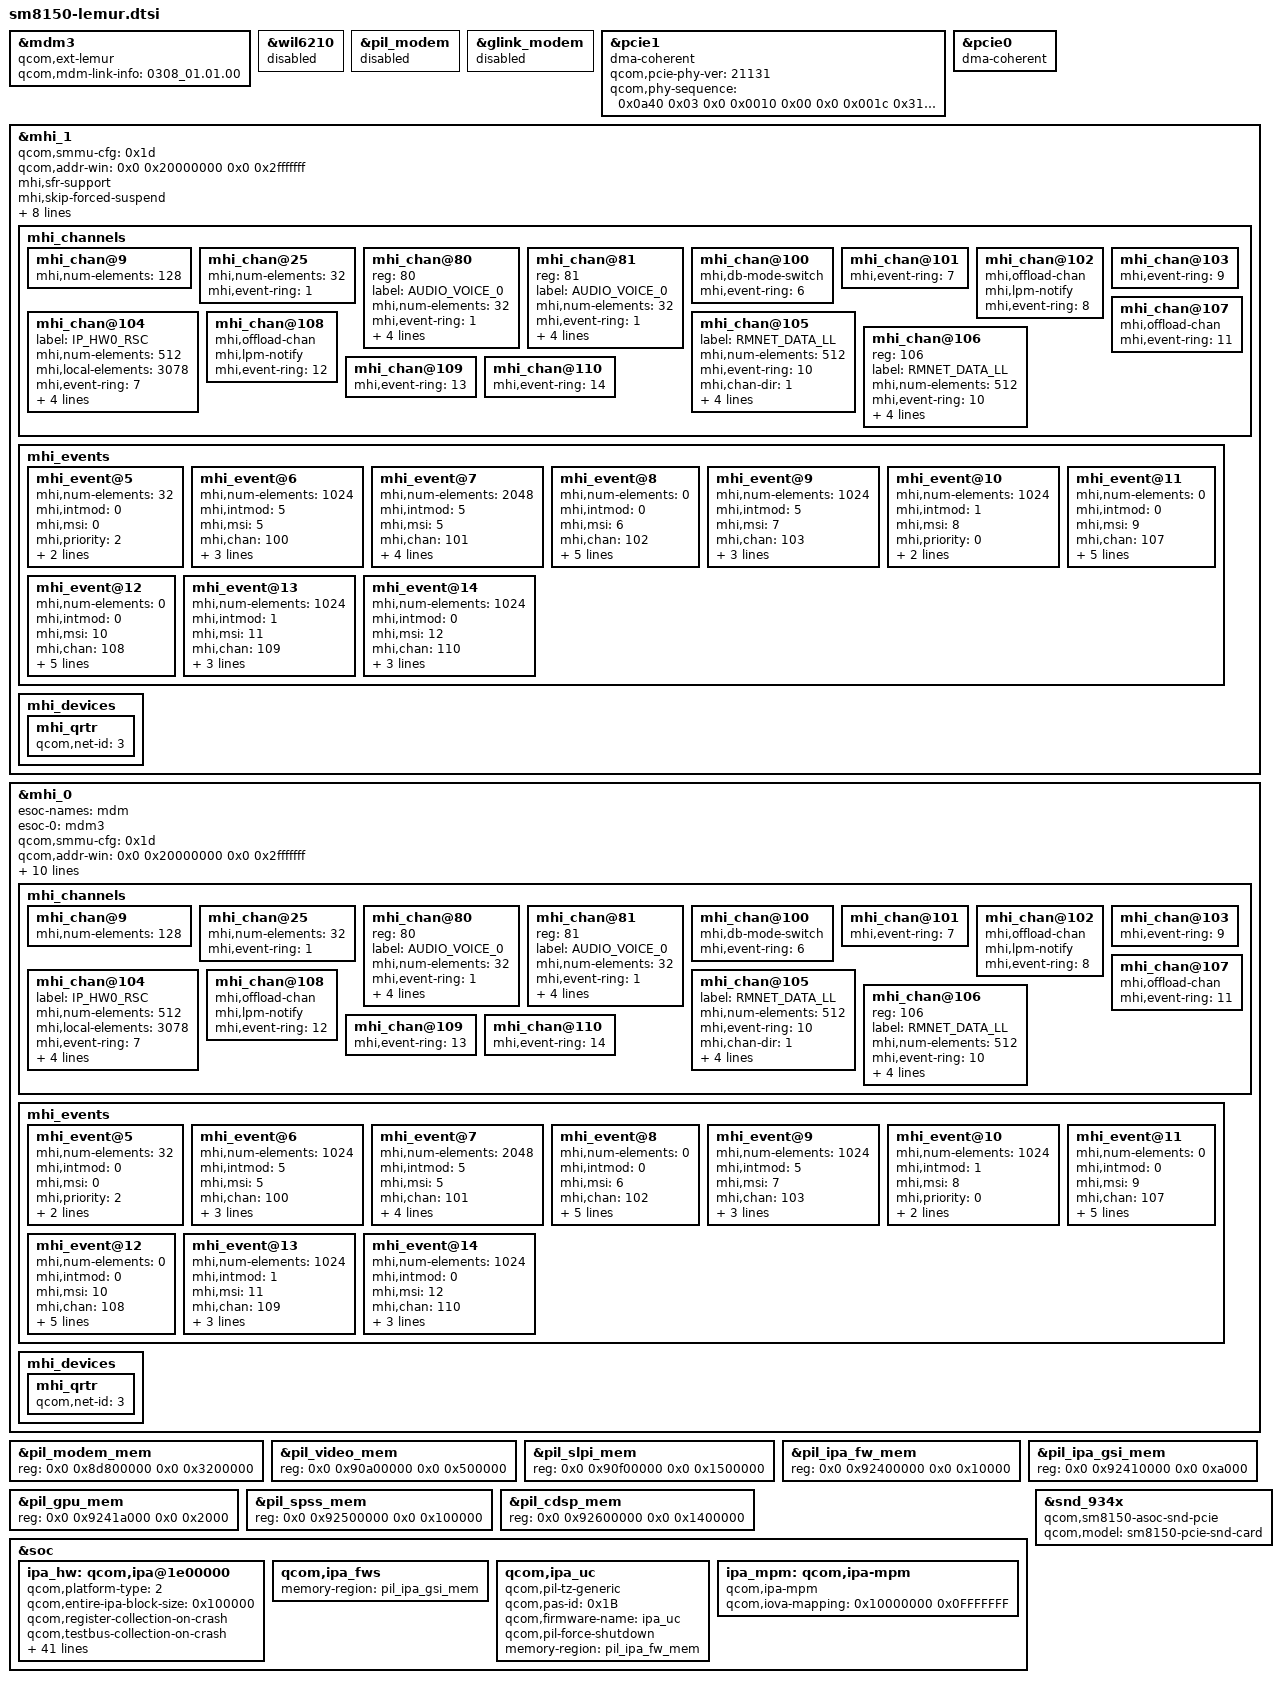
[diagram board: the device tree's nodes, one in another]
/* Copyright (c) 2020-2021, The Linux Foundation. All rights reserved.
 *
 * This program is free software; you can redistribute it and/or modify
 * it under the terms of the GNU General Public License version 2 and
 * only version 2 as published by the Free Software Foundation.
 *
 * This program is distributed in the hope that it will be useful,
 * but WITHOUT ANY WARRANTY; without even the implied warranty of
 * MERCHANTABILITY or FITNESS FOR A PARTICULAR PURPOSE.  See the
 * GNU General Public License for more details.
 */

#include <dt-bindings/msm/msm-bus-ids.h>
#include "sm8150-audio-overlay.dtsi"
#include "sdxlemur-thermal-common.dtsi"

&mdm3 {
	compatible = "qcom,ext-lemur";
	qcom,mdm-link-info = "0308_01.01.00";
};

&wil6210 {
	status = "disabled";
};

&pil_modem {
	status = "disabled";
};

&glink_modem {
	status = "disabled";
};

&pcie1 {
	dma-coherent;
	qcom,pcie-phy-ver = <21131>;
	qcom,phy-sequence = <0x0a40 0x03 0x0
			0x0010 0x00 0x0
			0x001c 0x31 0x0
			0x0020 0x01 0x0
			0x0024 0xde 0x0
			0x0028 0x07 0x0
			0x0030 0x4c 0x0
			0x0034 0x06 0x0
			0x0048 0x90 0x0
			0x0058 0x0f 0x0
			0x0074 0x06 0x0
			0x0078 0x06 0x0
			0x007c 0x16 0x0
			0x0080 0x16 0x0
			0x0084 0x36 0x0
			0x0088 0x36 0x0
			0x0094 0x08 0x0
			0x00a4 0x42 0x0
			0x00ac 0x0a 0x0
			0x00b0 0x1a 0x0
			0x00b4 0x14 0x0
			0x00b8 0x34 0x0
			0x00bc 0x82 0x0
			0x00c4 0x68 0x0
			0x00cc 0x55 0x0
			0x00d0 0x55 0x0
			0x00d4 0x03 0x0
			0x00d8 0xab 0x0
			0x00dc 0xaa 0x0
			0x00e0 0x02 0x0
			0x010c 0x02 0x0
			0x0110 0x24 0x0
			0x0118 0xb4 0x0
			0x011c 0x03 0x0
			0x0154 0x34 0x0
			0x0158 0x01 0x0
			0x016c 0x08 0x0
			0x01ac 0xb9 0x0
			0x01b0 0x1e 0x0
			0x01b4 0x94 0x0
			0x01b8 0x18 0x0
			0x01bc 0x11 0x0
			0x023c 0x11 0x0
			0x0284 0x35 0x0
			0x029c 0x12 0x0
			0x0304 0x02 0x0
			0x0408 0x0c 0x0
			0x0414 0x03 0x0
			0x0434 0x7f 0x0
			0x0444 0x70 0x0
			0x0460 0x30 0x0
			0x0464 0x00 0x0
			0x04d4 0x04 0x0
			0x04d8 0x07 0x0
			0x04dc 0x0d 0x0
			0x04e8 0x00 0x0
			0x04ec 0x0e 0x0
			0x04f0 0x4a 0x0
			0x04f4 0x0f 0x0
			0x04f8 0xc0 0x0
			0x04fc 0x00 0x0
			0x0510 0x17 0x0
			0x0518 0x1c 0x0
			0x051c 0x03 0x0
			0x0524 0x1e 0x0
			0x0570 0xff 0x0
			0x0574 0xff 0x0
			0x0578 0xff 0x0
			0x057c 0x7f 0x0
			0x0580 0x66 0x0
			0x0584 0x24 0x0
			0x0588 0xe4 0x0
			0x058c 0xec 0x0
			0x0590 0x3b 0x0
			0x0594 0x36 0x0
			0x0598 0xd4 0x0
			0x059c 0x54 0x0
			0x05a0 0xdb 0x0
			0x05a4 0x3b 0x0
			0x05a8 0x31 0x0
			0x05bc 0x0c 0x0
			0x063c 0x11 0x0
			0x0684 0x35 0x0
			0x069c 0x12 0x0
			0x0704 0x20 0x0
			0x0808 0x0c 0x0
			0x0814 0x03 0x0
			0x0834 0x7f 0x0
			0x0844 0x70 0x0
			0x0860 0x30 0x0
			0x0864 0x00 0x0
			0x08d4 0x04 0x0
			0x08d8 0x07 0x0
			0x08dc 0x0d 0x0
			0x08e8 0x00 0x0
			0x08ec 0x0e 0x0
			0x08f0 0x4a 0x0
			0x08f4 0x0f 0x0
			0x08f8 0xc0 0x0
			0x08fc 0x00 0x0
			0x0910 0x17 0x0
			0x0918 0x1c 0x0
			0x091c 0x03 0x0
			0x0924 0x1e 0x0
			0x0970 0xff 0x0
			0x0974 0xff 0x0
			0x0978 0xff 0x0
			0x097c 0x7f 0x0
			0x0980 0x66 0x0
			0x0984 0x24 0x0
			0x0988 0xe4 0x0
			0x098c 0xec 0x0
			0x0990 0x3b 0x0
			0x0994 0x36 0x0
			0x0998 0xd4 0x0
			0x099c 0x54 0x0
			0x09a0 0xdb 0x0
			0x09a4 0x3b 0x0
			0x09a8 0x31 0x0
			0x09bc 0x0c 0x0
			0x0adc 0x05 0x0
			0x0b88 0x88 0x0
			0x0b98 0x0b 0x0
			0x0ba4 0x01 0x0
			0x0bec 0x12 0x0
			0x0e0c 0x0d 0x0
			0x0e14 0x07 0x0
			0x0e1c 0xc1 0x0
			0x0e40 0x01 0x0
			0x0e48 0x01 0x0
			0x0e90 0x00 0x0
			0x0eb4 0x33 0x0
			0x0ebc 0x00 0x0
			0x0ee0 0x58 0x0
			0x0ea4 0x0f 0x0
			0x1028 0x50 0x0
			0x1428 0x50 0x0
			0x0a00 0x00 0x0
			0x0a44 0x03 0x0>;
};

&pcie0 {
	dma-coherent;
};

&mhi_1 {
	/* MHI1/RC0 does not include esoc support */
	qcom,smmu-cfg = <0x1d>;
	qcom,addr-win = <0x0 0x20000000 0x0 0x2fffffff>;
	mhi,sfr-support;
	mhi,skip-forced-suspend;

	/* controller noc frequency scaling configuration */
	qcom,msm-bus,name = "mhi1";
	qcom,msm-bus,num-cases = <4>;
	qcom,msm-bus,num-paths = <1>;
	qcom,msm-bus,vectors-KBps =
			<MSM_BUS_MASTER_PCIE_1 MSM_BUS_SLAVE_EBI_CH0
			0 0>,
			<MSM_BUS_MASTER_PCIE_1 MSM_BUS_SLAVE_EBI_CH0
			0 0>,
			<MSM_BUS_MASTER_PCIE_1 MSM_BUS_SLAVE_EBI_CH0
			500000 0>, /* 4 Gbps */
			<MSM_BUS_MASTER_PCIE_1 MSM_BUS_SLAVE_EBI_CH0
			1000000 0>; /* 8 Gbps */

	mhi_channels {
		#address-cells = <1>;
		#size-cells = <0>;

		mhi_chan@9 {
			mhi,num-elements = <128>;
		};

		mhi_chan@25 {
			mhi,num-elements = <32>;
			mhi,event-ring = <1>;
		};

		mhi_chan@80 {
			reg = <80>;
			label = "AUDIO_VOICE_0";
			mhi,num-elements = <32>;
			mhi,event-ring = <1>;
			mhi,chan-dir = <1>;
			mhi,data-type = <0>;
			mhi,doorbell-mode = <2>;
			mhi,ee = <0x4>;
		};

		mhi_chan@81 {
			reg = <81>;
			label = "AUDIO_VOICE_0";
			mhi,num-elements = <32>;
			mhi,event-ring = <1>;
			mhi,chan-dir = <2>;
			mhi,data-type = <0>;
			mhi,doorbell-mode = <2>;
			mhi,ee = <0x4>;
		};

		mhi_chan@100 {
			mhi,db-mode-switch;
			mhi,event-ring = <6>;
		};

		mhi_chan@101 {
			mhi,event-ring = <7>;
		};

		mhi_chan@102 {
			mhi,offload-chan;
			mhi,lpm-notify;
			mhi,event-ring = <8>;
		};

		mhi_chan@103 {
			mhi,event-ring = <9>;
		};

		mhi_chan@104 {
			label = "IP_HW0_RSC";
			mhi,num-elements = <512>;
			mhi,local-elements = <3078>;
			mhi,event-ring = <7>;
			mhi,chan-dir = <2>;
			mhi,data-type = <5>;
			mhi,doorbell-mode = <3>;
			mhi,chan-type = <3>;
		};

		mhi_chan@105 {
			label = "RMNET_DATA_LL";
			mhi,num-elements = <512>;
			mhi,event-ring = <10>;
			mhi,chan-dir = <1>;
			mhi,data-type = <1>;
			mhi,doorbell-mode = <3>;
			mhi,ee = <0x4>;
			mhi,db-mode-switch;
		};

		mhi_chan@106 {
			reg = <106>;
			label = "RMNET_DATA_LL";
			mhi,num-elements = <512>;
			mhi,event-ring = <10>;
			mhi,chan-dir = <2>;
			mhi,data-type = <0>;
			mhi,doorbell-mode = <3>;
			mhi,ee = <0x4>;
		};

		mhi_chan@107 {
			mhi,offload-chan;
			mhi,event-ring = <11>;
		};

		mhi_chan@108 {
			mhi,offload-chan;
			mhi,lpm-notify;
			mhi,event-ring = <12>;
		};

		mhi_chan@109 {
			mhi,event-ring = <13>;
		};

		mhi_chan@110 {
			mhi,event-ring = <14>;
		};
	};

	mhi_events {
		#address-cells = <1>;
		#size-cells = <0>;

		mhi_event@5 {
			mhi,num-elements = <32>;
			mhi,intmod = <0>;
			mhi,msi = <0>;
			mhi,priority = <2>;
			mhi,brstmode = <2>;
			mhi,data-type = <2>;
		};

		mhi_event@6 {
			mhi,num-elements = <1024>;
			mhi,intmod = <5>;
			mhi,msi = <5>;
			mhi,chan = <100>;
			mhi,priority = <1>;
			mhi,brstmode = <3>;
			mhi,hw-ev;
		};

		mhi_event@7 {
			mhi,num-elements = <2048>;
			mhi,intmod = <5>;
			mhi,msi = <5>;
			mhi,chan = <101>;
			mhi,priority = <1>;
			mhi,brstmode = <3>;
			mhi,hw-ev;
			mhi,client-manage;
		};

		mhi_event@8 {
			mhi,num-elements = <0>;
			mhi,intmod = <0>;
			mhi,msi = <6>;
			mhi,chan = <102>;
			mhi,priority = <1>;
			mhi,brstmode = <3>;
			mhi,hw-ev;
			mhi,client-manage;
			mhi,offload;
		};

		mhi_event@9 {
			mhi,num-elements = <1024>;
			mhi,intmod = <5>;
			mhi,msi = <7>;
			mhi,chan = <103>;
			mhi,priority = <1>;
			mhi,brstmode = <2>;
			mhi,hw-ev;
		};

		mhi_event@10 {
			mhi,num-elements = <1024>;
			mhi,intmod = <1>;
			mhi,msi = <8>;
			mhi,priority = <0>;
			mhi,brstmode = <3>;
			mhi,hw-ev;
		};

		mhi_event@11 {
			mhi,num-elements = <0>;
			mhi,intmod = <0>;
			mhi,msi = <9>;
			mhi,chan = <107>;
			mhi,priority = <1>;
			mhi,brstmode = <3>;
			mhi,hw-ev;
			mhi,client-manage;
			mhi,offload;
		};

		mhi_event@12 {
			mhi,num-elements = <0>;
			mhi,intmod = <0>;
			mhi,msi = <10>;
			mhi,chan = <108>;
			mhi,priority = <1>;
			mhi,brstmode = <3>;
			mhi,hw-ev;
			mhi,client-manage;
			mhi,offload;
		};

		mhi_event@13 {
			mhi,num-elements = <1024>;
			mhi,intmod = <1>;
			mhi,msi = <11>;
			mhi,chan = <109>;
			mhi,priority = <0>;
			mhi,brstmode = <2>;
			mhi,hw-ev;
		};

		mhi_event@14 {
			mhi,num-elements = <1024>;
			mhi,intmod = <0>;
			mhi,msi = <12>;
			mhi,chan = <110>;
			mhi,priority = <0>;
			mhi,brstmode = <2>;
			mhi,hw-ev;
		};
	};

	mhi_devices {
		mhi_qrtr {
			qcom,net-id = <3>;
		};
	};
};

&mhi_0 {
	esoc-names = "mdm";
	esoc-0 = <&mdm3>;
	qcom,smmu-cfg = <0x1d>;
	qcom,addr-win = <0x0 0x20000000 0x0 0x2fffffff>;
	mhi,sfr-support;
	mhi,skip-forced-suspend;

	/* controller noc frequency scaling configuration */
	qcom,msm-bus,name = "mhi0";
	qcom,msm-bus,num-cases = <4>;
	qcom,msm-bus,num-paths = <1>;
	qcom,msm-bus,vectors-KBps =
			<MSM_BUS_MASTER_PCIE_1 MSM_BUS_SLAVE_EBI_CH0
			0 0>,
			<MSM_BUS_MASTER_PCIE_1 MSM_BUS_SLAVE_EBI_CH0
			0 0>,
			<MSM_BUS_MASTER_PCIE_1 MSM_BUS_SLAVE_EBI_CH0
			500000 0>, /* 4 Gbps */
			<MSM_BUS_MASTER_PCIE_1 MSM_BUS_SLAVE_EBI_CH0
			1000000 0>; /* 8 Gbps */

	mhi_channels {
		#address-cells = <1>;
		#size-cells = <0>;

		mhi_chan@9 {
			mhi,num-elements = <128>;
		};

		mhi_chan@25 {
			mhi,num-elements = <32>;
			mhi,event-ring = <1>;
		};

		mhi_chan@80 {
			reg = <80>;
			label = "AUDIO_VOICE_0";
			mhi,num-elements = <32>;
			mhi,event-ring = <1>;
			mhi,chan-dir = <1>;
			mhi,data-type = <0>;
			mhi,doorbell-mode = <2>;
			mhi,ee = <0x4>;
		};

		mhi_chan@81 {
			reg = <81>;
			label = "AUDIO_VOICE_0";
			mhi,num-elements = <32>;
			mhi,event-ring = <1>;
			mhi,chan-dir = <2>;
			mhi,data-type = <0>;
			mhi,doorbell-mode = <2>;
			mhi,ee = <0x4>;
		};

		mhi_chan@100 {
			mhi,db-mode-switch;
			mhi,event-ring = <6>;
		};

		mhi_chan@101 {
			mhi,event-ring = <7>;
		};

		mhi_chan@102 {
			mhi,offload-chan;
			mhi,lpm-notify;
			mhi,event-ring = <8>;
		};

		mhi_chan@103 {
			mhi,event-ring = <9>;
		};

		mhi_chan@104 {
			label = "IP_HW0_RSC";
			mhi,num-elements = <512>;
			mhi,local-elements = <3078>;
			mhi,event-ring = <7>;
			mhi,chan-dir = <2>;
			mhi,data-type = <5>;
			mhi,doorbell-mode = <3>;
			mhi,chan-type = <3>;
		};

		mhi_chan@105 {
			label = "RMNET_DATA_LL";
			mhi,num-elements = <512>;
			mhi,event-ring = <10>;
			mhi,chan-dir = <1>;
			mhi,data-type = <1>;
			mhi,doorbell-mode = <3>;
			mhi,ee = <0x4>;
			mhi,db-mode-switch;
		};

		mhi_chan@106 {
			reg = <106>;
			label = "RMNET_DATA_LL";
			mhi,num-elements = <512>;
			mhi,event-ring = <10>;
			mhi,chan-dir = <2>;
			mhi,data-type = <0>;
			mhi,doorbell-mode = <3>;
			mhi,ee = <0x4>;
		};

		mhi_chan@107 {
			mhi,offload-chan;
			mhi,event-ring = <11>;
		};

		mhi_chan@108 {
			mhi,offload-chan;
			mhi,lpm-notify;
			mhi,event-ring = <12>;
		};

		mhi_chan@109 {
			mhi,event-ring = <13>;
		};

		mhi_chan@110 {
			mhi,event-ring = <14>;
		};
	};

	mhi_events {
		#address-cells = <1>;
		#size-cells = <0>;

		mhi_event@5 {
			mhi,num-elements = <32>;
			mhi,intmod = <0>;
			mhi,msi = <0>;
			mhi,priority = <2>;
			mhi,brstmode = <2>;
			mhi,data-type = <2>;
		};

		mhi_event@6 {
			mhi,num-elements = <1024>;
			mhi,intmod = <5>;
			mhi,msi = <5>;
			mhi,chan = <100>;
			mhi,priority = <1>;
			mhi,brstmode = <3>;
			mhi,hw-ev;
		};

		mhi_event@7 {
			mhi,num-elements = <2048>;
			mhi,intmod = <5>;
			mhi,msi = <5>;
			mhi,chan = <101>;
			mhi,priority = <1>;
			mhi,brstmode = <3>;
			mhi,hw-ev;
			mhi,client-manage;
		};

		mhi_event@8 {
			mhi,num-elements = <0>;
			mhi,intmod = <0>;
			mhi,msi = <6>;
			mhi,chan = <102>;
			mhi,priority = <1>;
			mhi,brstmode = <3>;
			mhi,hw-ev;
			mhi,client-manage;
			mhi,offload;
		};

		mhi_event@9 {
			mhi,num-elements = <1024>;
			mhi,intmod = <5>;
			mhi,msi = <7>;
			mhi,chan = <103>;
			mhi,priority = <1>;
			mhi,brstmode = <2>;
			mhi,hw-ev;
		};

		mhi_event@10 {
			mhi,num-elements = <1024>;
			mhi,intmod = <1>;
			mhi,msi = <8>;
			mhi,priority = <0>;
			mhi,brstmode = <3>;
			mhi,hw-ev;
		};

		mhi_event@11 {
			mhi,num-elements = <0>;
			mhi,intmod = <0>;
			mhi,msi = <9>;
			mhi,chan = <107>;
			mhi,priority = <1>;
			mhi,brstmode = <3>;
			mhi,hw-ev;
			mhi,client-manage;
			mhi,offload;
		};

		mhi_event@12 {
			mhi,num-elements = <0>;
			mhi,intmod = <0>;
			mhi,msi = <10>;
			mhi,chan = <108>;
			mhi,priority = <1>;
			mhi,brstmode = <3>;
			mhi,hw-ev;
			mhi,client-manage;
			mhi,offload;
		};

		mhi_event@13 {
			mhi,num-elements = <1024>;
			mhi,intmod = <1>;
			mhi,msi = <11>;
			mhi,chan = <109>;
			mhi,priority = <0>;
			mhi,brstmode = <2>;
			mhi,hw-ev;
		};

		mhi_event@14 {
			mhi,num-elements = <1024>;
			mhi,intmod = <0>;
			mhi,msi = <12>;
			mhi,chan = <110>;
			mhi,priority = <0>;
			mhi,brstmode = <2>;
			mhi,hw-ev;
		};
	};

	mhi_devices {
		mhi_qrtr {
			qcom,net-id = <3>;
		};
	};
};

&pil_modem_mem {
	reg = <0x0 0x8d800000 0x0 0x3200000>;
};

&pil_video_mem {
	reg = <0x0 0x90a00000 0x0 0x500000>;
};

&pil_slpi_mem {
	reg = <0x0 0x90f00000 0x0 0x1500000>;
};

&pil_ipa_fw_mem {
	reg = <0x0 0x92400000 0x0 0x10000>;
};

&pil_ipa_gsi_mem {
	reg = <0x0 0x92410000 0x0 0xa000>;
};

&pil_gpu_mem {
	reg = <0x0 0x9241a000 0x0 0x2000>;
};

&pil_spss_mem {
	reg = <0x0 0x92500000 0x0 0x100000>;
};

&pil_cdsp_mem {
	reg = <0x0 0x92600000 0x0 0x1400000>;
};

&soc {
	ipa_hw: qcom,ipa@1e00000 {
		qcom,platform-type = <2>; /* APQ platform */
		qcom,entire-ipa-block-size = <0x100000>;
		qcom,register-collection-on-crash;
		qcom,testbus-collection-on-crash;
		qcom,non-tn-collection-on-crash;
		qcom,secure-debug-check-action = <0>;
		qcom,msm-bus,name = "ipa";
		qcom,msm-bus,num-cases = <5>;
		qcom,msm-bus,num-paths = <6>;
		qcom,msm-bus,vectors-KBps =
		/* No vote */
		<MSM_BUS_MASTER_IPA MSM_BUS_SLAVE_SNOC_GEM_NOC_SF 0 0>,
		<MSM_BUS_MASTER_SNOC_SF_MEM_NOC MSM_BUS_SLAVE_LLCC 0 0>,
		<MSM_BUS_MASTER_LLCC MSM_BUS_SLAVE_EBI_CH0 0 0>,
		<MSM_BUS_MASTER_IPA MSM_BUS_SLAVE_OCIMEM 0 0>,
		<MSM_BUS_MASTER_AMPSS_M0 MSM_BUS_SLAVE_IPA_CFG 0 0>,
		<MSM_BUS_MASTER_IPA_CORE MSM_BUS_SLAVE_IPA_CORE 0 0>,

		/* SVS2 */
		<MSM_BUS_MASTER_IPA MSM_BUS_SLAVE_SNOC_GEM_NOC_SF
			150000 750000>,
		<MSM_BUS_MASTER_SNOC_SF_MEM_NOC MSM_BUS_SLAVE_LLCC
			150000 4789750>,
		<MSM_BUS_MASTER_LLCC MSM_BUS_SLAVE_EBI_CH0 150000 1800000>,
		<MSM_BUS_MASTER_IPA MSM_BUS_SLAVE_OCIMEM 80000 350000>,
		<MSM_BUS_MASTER_AMPSS_M0 MSM_BUS_SLAVE_IPA_CFG 40000 40000>,
		<MSM_BUS_MASTER_IPA_CORE MSM_BUS_SLAVE_IPA_CORE 0 125>,

		/* SVS */
		<MSM_BUS_MASTER_IPA MSM_BUS_SLAVE_SNOC_GEM_NOC_SF
			150000 1500000>,
		<MSM_BUS_MASTER_SNOC_SF_MEM_NOC MSM_BUS_SLAVE_LLCC
			150000 7429000>,
		<MSM_BUS_MASTER_LLCC MSM_BUS_SLAVE_EBI_CH0 625000 3070000>,
		<MSM_BUS_MASTER_IPA MSM_BUS_SLAVE_OCIMEM 80000 640000>,
		<MSM_BUS_MASTER_AMPSS_M0 MSM_BUS_SLAVE_IPA_CFG 80000 80000>,
		<MSM_BUS_MASTER_IPA_CORE MSM_BUS_SLAVE_IPA_CORE 0 250>,

		/* NOMINAL */
		<MSM_BUS_MASTER_IPA MSM_BUS_SLAVE_SNOC_GEM_NOC_SF
			150000 3000000>,
		<MSM_BUS_MASTER_SNOC_SF_MEM_NOC MSM_BUS_SLAVE_LLCC
			150000 8797500>,
		<MSM_BUS_MASTER_LLCC MSM_BUS_SLAVE_EBI_CH0 1250000 6220000>,
		<MSM_BUS_MASTER_IPA MSM_BUS_SLAVE_OCIMEM 206000 960000>,
		<MSM_BUS_MASTER_AMPSS_M0 MSM_BUS_SLAVE_IPA_CFG 206000 160000>,
		<MSM_BUS_MASTER_IPA_CORE MSM_BUS_SLAVE_IPA_CORE 0 500>,

		/* TURBO */
		<MSM_BUS_MASTER_IPA MSM_BUS_SLAVE_SNOC_GEM_NOC_SF
			150000 4000000>,
		<MSM_BUS_MASTER_SNOC_SF_MEM_NOC MSM_BUS_SLAVE_LLCC
			150000 15640000>,
		<MSM_BUS_MASTER_LLCC MSM_BUS_SLAVE_EBI_CH0 2000000 7219000>,
		<MSM_BUS_MASTER_IPA MSM_BUS_SLAVE_OCIMEM 206000 1600000>,
		<MSM_BUS_MASTER_AMPSS_M0 MSM_BUS_SLAVE_IPA_CFG 206000 300000>,
		<MSM_BUS_MASTER_IPA_CORE MSM_BUS_SLAVE_IPA_CORE 0 600>;

		qcom,bus-vector-names = "MIN", "SVS2", "SVS", "NOMINAL",
		"TURBO";

		qcom,throughput-threshold = <600 2500 5000>;
		qcom,scaling-exceptions = "wdi", "0", "600", "1200",
			"USB DPL", "0", "2500", "5000", "ODL", "0",
			"2500", "5000";
	};

	qcom,ipa_fws {
		memory-region = <&pil_ipa_gsi_mem>;
	};

	qcom,ipa_uc {
		compatible = "qcom,pil-tz-generic";
		qcom,pas-id = <0x1B>;
		qcom,firmware-name = "ipa_uc";
		qcom,pil-force-shutdown;
		memory-region = <&pil_ipa_fw_mem>;
	};
	ipa_mpm: qcom,ipa-mpm {
		compatible = "qcom,ipa-mpm";
		qcom,iova-mapping = <0x10000000 0x0FFFFFFF>;
	 };
};

&snd_934x {
	compatible = "qcom,sm8150-asoc-snd-pcie";
	qcom,model = "sm8150-pcie-snd-card";
};
